# STM32F446ZET7 register map
File version: 1.0
Registers are 32-bit, access not given, reset 0x0 unless marked. A register's access mark holds for its fields unless they carry their own. Offsets are from the block's base; [hi:lo] are bit positions; {n}, {i} and the like mark numbered series; 'fields as' and 'values as' point back to an identical list.

## SYSCFG
Base 0x40013800
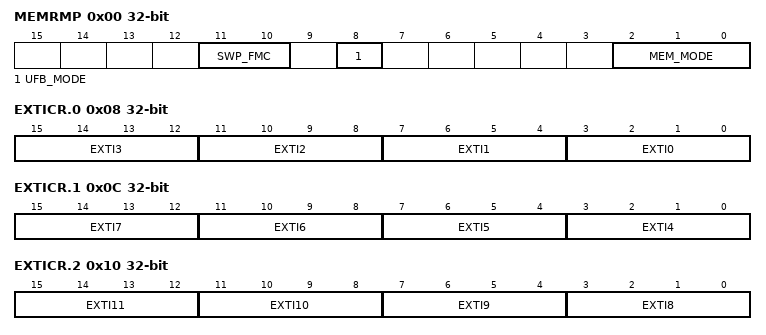
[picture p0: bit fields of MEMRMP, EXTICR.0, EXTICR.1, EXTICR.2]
0x00 MEMRMP
  [11:10] SWP_FMC, [8] UFB_MODE, [2:0] MEM_MODE
0x04 PMC
  [18] ADC3DC2, [17] ADC2DC2, [18:16] ADCxDC2
0x08 EXTICR.0
  [4n+3:4n] EXTI{n} (n=0..3)
0x0C EXTICR.1
  [4n-13:4n-16] EXTI{n} (n=4..7)
0x10 EXTICR.2
  [4n-29:4n-32] EXTI{n} (n=8..11)
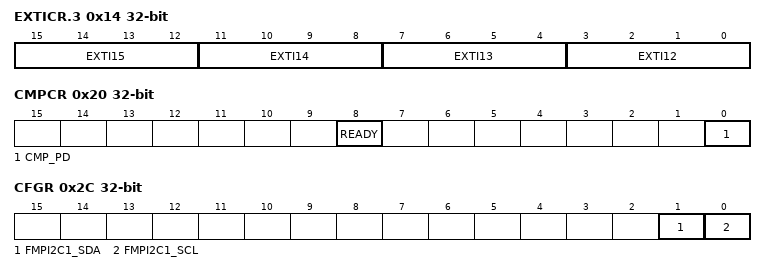
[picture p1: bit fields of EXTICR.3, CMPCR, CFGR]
0x14 EXTICR.3
  [4n-45:4n-48] EXTI{n} (n=12..15)
0x20 CMPCR
  [8] READY, [0] CMP_PD
0x2C CFGR
  [1] FMPI2C1_SDA, [0] FMPI2C1_SCL

## EXTI
Base 0x40013C00
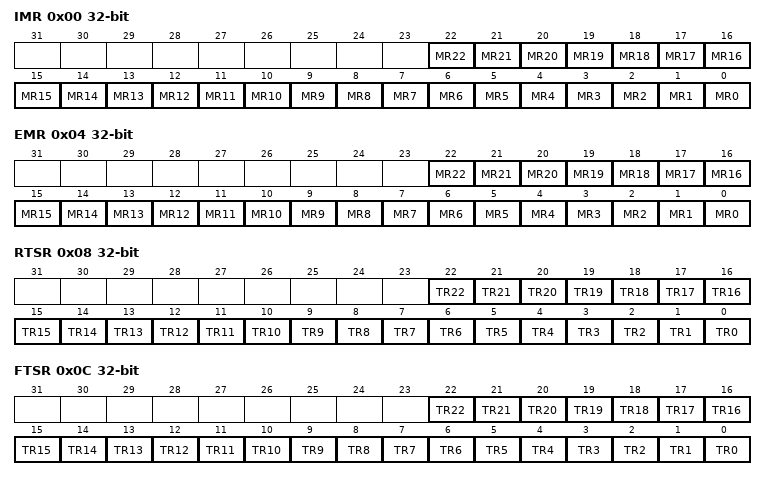
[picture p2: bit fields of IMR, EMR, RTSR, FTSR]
0x00 IMR
  [n] MR{n} (n=0..22)
0x04 EMR
  [n] MR{n} (n=0..22)
0x08 RTSR
  [n] TR{n} (n=0..22)
0x0C FTSR
  [n] TR{n} (n=0..22)
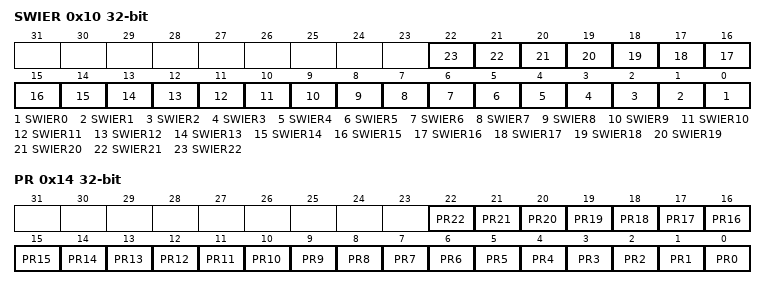
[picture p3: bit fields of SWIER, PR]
0x10 SWIER
  [n] SWIER{n} (n=0..22)
0x14 PR
  [n] PR{n} (n=0..22)

## SAI1
Base 0x40015800
Same registers: SAI2 0x40015C00
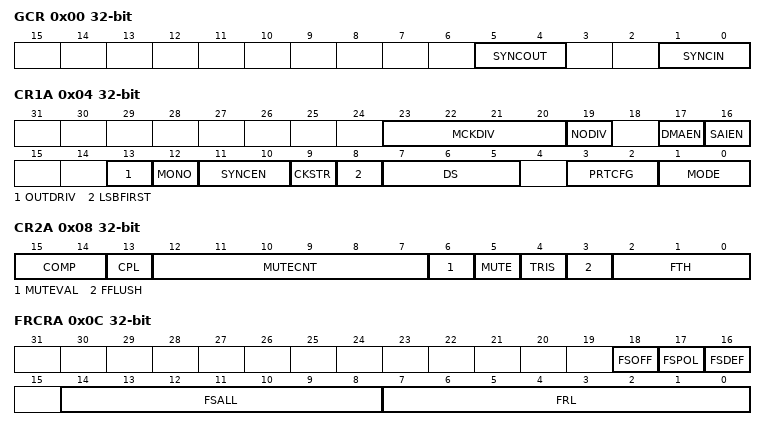
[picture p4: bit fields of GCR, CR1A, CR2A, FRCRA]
0x00 GCR
  [5:4] SYNCOUT, [1:0] SYNCIN
0x04 CR1A
  [23:20] MCKDIV, [19] NODIV, [17] DMAEN, [16] SAIEN, [13] OUTDRIV, [12] MONO, [11:10] SYNCEN, [9] CKSTR, [8] LSBFIRST, [7:5] DS, [3:2] PRTCFG, [1:0] MODE
0x08 CR2A
  [15:14] COMP, [13] CPL, [12:7] MUTECNT, [6] MUTEVAL, [5] MUTE, [4] TRIS, [3] FFLUSH, [2:0] FTH
0x0C FRCRA
  [18] FSOFF, [17] FSPOL, [16] FSDEF, [14:8] FSALL, [7:0] FRL
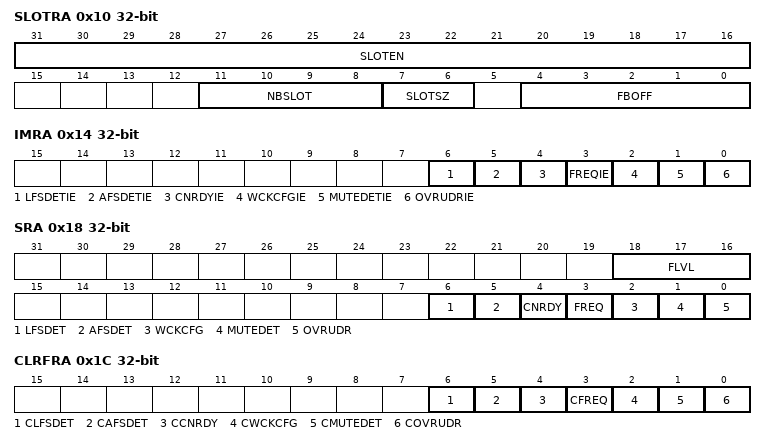
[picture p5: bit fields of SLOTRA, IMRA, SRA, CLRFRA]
0x10 SLOTRA
  [31:16] SLOTEN, [11:8] NBSLOT, [7:6] SLOTSZ, [4:0] FBOFF
0x14 IMRA
  [6] LFSDETIE, [5] AFSDETIE, [4] CNRDYIE, [3] FREQIE, [2] WCKCFGIE, [1] MUTEDETIE, [0] OVRUDRIE
0x18 SRA
  [18:16] FLVL, [6] LFSDET, [5] AFSDET, [4] CNRDY, [3] FREQ, [2] WCKCFG, [1] MUTEDET, [0] OVRUDR
0x1C CLRFRA
  [6] CLFSDET, [5] CAFSDET, [4] CCNRDY, [3] CFREQ, [2] CWCKCFG, [1] CMUTEDET, [0] COVRUDR
0x20 DRA
  [31:0] DATA
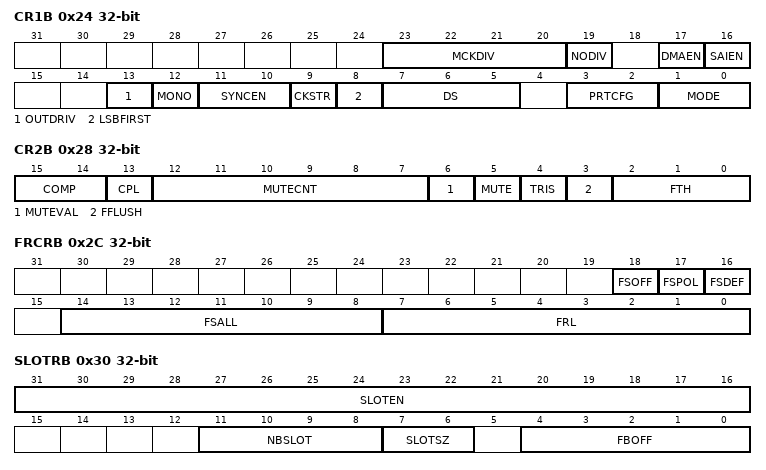
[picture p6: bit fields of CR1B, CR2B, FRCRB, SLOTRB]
0x24 CR1B
  fields as CR1A
0x28 CR2B
  fields as CR2A
0x2C FRCRB
  [18] FSOFF, [17] FSPOL, [16] FSDEF, [14:8] FSALL, [7:0] FRL
0x30 SLOTRB
  [31:16] SLOTEN, [11:8] NBSLOT, [7:6] SLOTSZ, [4:0] FBOFF
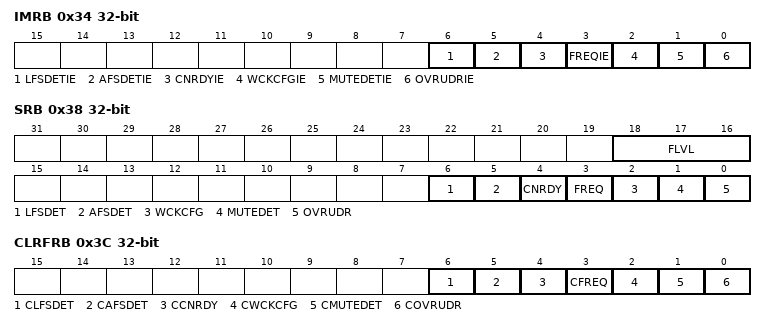
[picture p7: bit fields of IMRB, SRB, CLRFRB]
0x34 IMRB
  fields as IMRA
0x38 SRB
  fields as SRA
0x3C CLRFRB
  fields as CLRFRA
0x40 DRB
  [31:0] DATA

## GPIOA
Base 0x40020000
Same registers: GPIOB 0x40020400, GPIOC 0x40020800, GPIOD 0x40020C00, GPIOE 0x40021000, GPIOF 0x40021400, GPIOG 0x40021800, GPIOH 0x40021C00
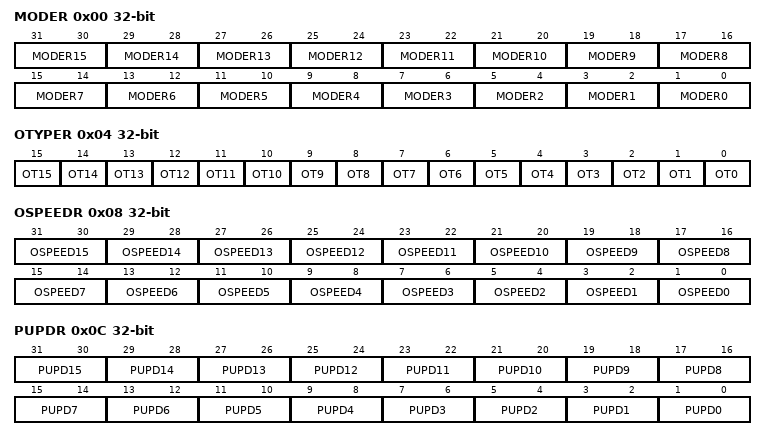
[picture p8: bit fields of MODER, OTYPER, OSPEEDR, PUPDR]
0x00 MODER
  [2n+1:2n] MODER{n} (n=0..15)
0x04 OTYPER
  [n] OT{n} (n=0..15)
0x08 OSPEEDR
  [2n+1:2n] OSPEED{n} (n=0..15)
0x0C PUPDR
  [2n+1:2n] PUPD{n} (n=0..15)
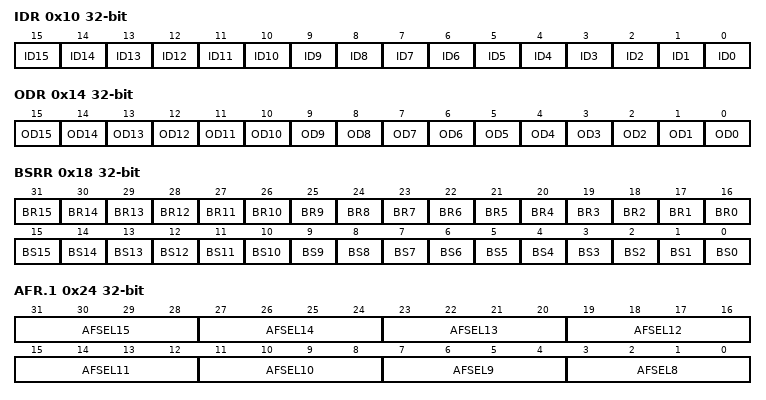
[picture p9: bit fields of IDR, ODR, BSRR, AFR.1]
0x10 IDR
  [n] ID{n} (n=0..15)
0x14 ODR
  [n] OD{n} (n=0..15)
0x18 BSRR
  [n+16] BR{n} (n=0..15), [n] BS{n} (n=0..15)
0x1C LCKR
0x20 AFR.0
0x24 AFR.1
  [4n-29:4n-32] AFSEL{n} (n=8..15)

## CRC
Base 0x40023000
0x00 DR
0x04 IDR 8-bit
0x08 CR
  [0] RESET

## FLASH
Base 0x40023C00
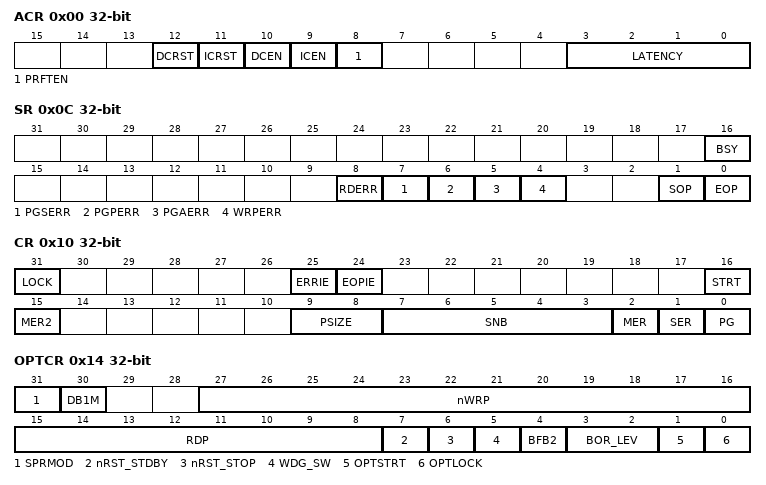
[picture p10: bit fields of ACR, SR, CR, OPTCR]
0x00 ACR
  [12] DCRST, [11] ICRST, [10] DCEN, [9] ICEN, [8] PRFTEN, [3:0] LATENCY
0x04 KEYR
0x08 OPTKEYR
0x0C SR
  [16] BSY, [8] RDERR, [7] PGSERR, [6] PGPERR, [5] PGAERR, [4] WRPERR, [1] SOP, [0] EOP
0x10 CR
  [31] LOCK, [25] ERRIE, [24] EOPIE, [16] STRT, [15] MER2, [9:8] PSIZE, [7:3] SNB, [2] MER, [1] SER, [0] PG
0x14 OPTCR
  [31] SPRMOD, [30] DB1M, [27:16] nWRP, [15:8] RDP, [7] nRST_STDBY, [6] nRST_STOP, [5] WDG_SW, [4] BFB2, [3:2] BOR_LEV, [1] OPTSTRT, [0] OPTLOCK
0x18 OPTCR1
  [27:16] nWRP

## DMA1
Base 0x40026000
Same registers: DMA2 0x40026400
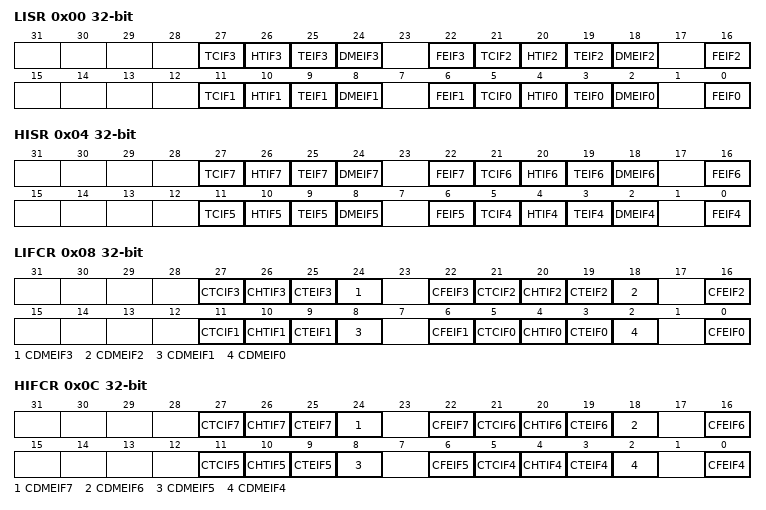
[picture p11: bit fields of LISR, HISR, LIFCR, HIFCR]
0x00 LISR
  [27] TCIF3, [26] HTIF3, [25] TEIF3, [24] DMEIF3, [22] FEIF3, [21] TCIF2, [20] HTIF2, [19] TEIF2, [18] DMEIF2, [16] FEIF2, [11] TCIF1, [10] HTIF1, [9] TEIF1, [8] DMEIF1, [6] FEIF1, [5] TCIF0, [4] HTIF0, [3] TEIF0, [2] DMEIF0, [0] FEIF0
0x04 HISR
  [27] TCIF7, [26] HTIF7, [25] TEIF7, [24] DMEIF7, [22] FEIF7, [21] TCIF6, [20] HTIF6, [19] TEIF6, [18] DMEIF6, [16] FEIF6, [11] TCIF5, [10] HTIF5, [9] TEIF5, [8] DMEIF5, [6] FEIF5, [5] TCIF4, [4] HTIF4, [3] TEIF4, [2] DMEIF4, [0] FEIF4
0x08 LIFCR
  [27] CTCIF3, [26] CHTIF3, [25] CTEIF3, [24] CDMEIF3, [22] CFEIF3, [21] CTCIF2, [20] CHTIF2, [19] CTEIF2, [18] CDMEIF2, [16] CFEIF2, [11] CTCIF1, [10] CHTIF1, [9] CTEIF1, [8] CDMEIF1, [6] CFEIF1, [5] CTCIF0, [4] CHTIF0, [3] CTEIF0, [2] CDMEIF0, [0] CFEIF0
0x0C HIFCR
  [27] CTCIF7, [26] CHTIF7, [25] CTEIF7, [24] CDMEIF7, [22] CFEIF7, [21] CTCIF6, [20] CHTIF6, [19] CTEIF6, [18] CDMEIF6, [16] CFEIF6, [11] CTCIF5, [10] CHTIF5, [9] CTEIF5, [8] CDMEIF5, [6] CFEIF5, [5] CTCIF4, [4] CHTIF4, [3] CTEIF4, [2] CDMEIF4, [0] CFEIF4
{0x10+0x18*i} CR{i} (i=0..7)
{0x14+0x18*i} NDTR{i} (i=0..7)
{0x18+0x18*i} PAR{i} (i=0..7)
{0x1C+0x18*i} M0AR{i} (i=0..7)
{0x20+0x18*i} M1AR{i} (i=0..7)
{0x24+0x18*i} FCR{i} (i=0..7)
